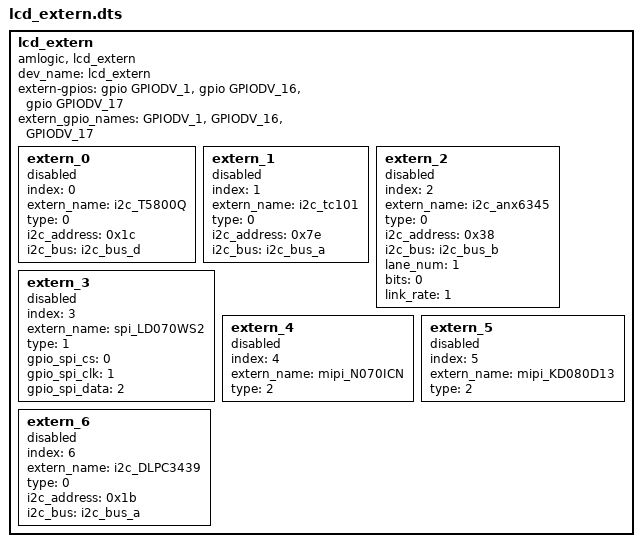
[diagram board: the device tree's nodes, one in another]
/*
 * drivers/amlogic/media/vout/lcd/lcd_extern/lcd_extern.dts
 *
 * Copyright (C) 2017 Amlogic, Inc. All rights reserved.
 *
 * This program is free software; you can redistribute it and/or modify
 * it under the terms of the GNU General Public License as published by
 * the Free Software Foundation; either version 2 of the License, or
 * (at your option) any later version.
 *
 * This program is distributed in the hope that it will be useful, but WITHOUT
 * ANY WARRANTY; without even the implied warranty of MERCHANTABILITY or
 * FITNESS FOR A PARTICULAR PURPOSE.  See the GNU General Public License for
 * more details.
 *
 */

lcd_extern{
	compatible = "amlogic, lcd_extern";
	dev_name = "lcd_extern";
	status = "okay";

	extern-gpios = <&gpio GPIODV_1 GPIO_ACTIVE_HIGH
			&gpio GPIODV_16 GPIO_ACTIVE_HIGH
			&gpio GPIODV_17 GPIO_ACTIVE_HIGH>;
	extern_gpio_names = "GPIODV_1","GPIODV_16","GPIODV_17";

	extern_0{
		index = <0>;
		extern_name = "i2c_T5800Q";
		status = "disabled";

		type = <0>; /** lcd_extern_driver type: 0=i2c, 1=spi, 2=mipi */
		i2c_address = <0x1c>; /** 7bit i2c address */
		i2c_bus = "i2c_bus_d";
	};

	extern_1{
		index = <1>;
		extern_name = "i2c_tc101";
		status = "disabled";

		type = <0>; /** lcd_extern_driver type: 0=i2c, 1=spi, 2=mipi */
		i2c_address = <0x7e>; /** 7bit i2c address */
		i2c_bus = "i2c_bus_a";
	};

	extern_2{
		index = <2>;
		extern_name = "i2c_anx6345";
		status = "disabled";

		type = <0>; /** lcd_extern_driver type: 0=i2c, 1=spi, 2=mipi */
		i2c_address = <0x38>; /** 7bit i2c address */
		i2c_bus = "i2c_bus_b";
		lane_num = <1>; /** edp lane_num: 1/2/4 */
		bits = <0>;  /** lcd_bits(0=6bit, 1=8bit) */
		link_rate = <1>; /** edp link rate: (0=1.62G, 1=27G, 2=5.4G) */
	};

	extern_3{
		index = <3>;
		extern_name = "spi_LD070WS2";
		status = "disabled";

		type = <1>; /** lcd_extern_driver type: 0=i2c, 1=spi, 2=mipi */

		gpio_spi_cs = <0>; /* index in extern-gpios */
		gpio_spi_clk = <1>; /* index in extern-gpios */
		gpio_spi_data = <2>; /* index in extern-gpios */
	};

	extern_4{
		index = <4>;
		extern_name = "mipi_N070ICN";
		status = "disabled";

		type = <2>; /** lcd_extern_driver type: 0=i2c, 1=spi, 2=mipi */
	};

	extern_5{
		index = <5>;
		extern_name = "mipi_KD080D13";
		status = "disabled";

		type = <2>; /** lcd_extern_driver type: 0=i2c, 1=spi, 2=mipi */
	};

	extern_6{
		index = <6>;
		extern_name = "i2c_DLPC3439";
		status = "disabled";

		type = <0>; /** lcd_extern_driver type: 0=i2c, 1=spi, 2=mipi */
		i2c_address = <0x1b>; /** 7bit i2c address */
		i2c_bus = "i2c_bus_a";
	};
};

